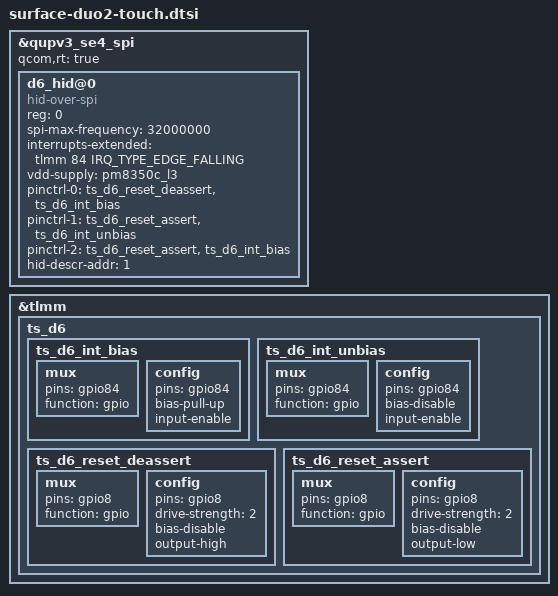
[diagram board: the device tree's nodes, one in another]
/*
 * Copyright (c) 2020 Microsoft Corporation
 *
 * This program is free software; you can redistribute it and/or modify it
 * under the terms of the GNU General Public License version 2 as published by
 * the Free Software Foundation.
 */
#include <dt-bindings/interrupt-controller/irq.h>

&qupv3_se4_spi {
	status = "okay";
	qcom,rt = "true";

	d6_hid@0 {
		compatible = "hid-over-spi";
		reg = <0>;
		spi-max-frequency = <32000000>;
		interrupts-extended = <&tlmm 84 IRQ_TYPE_EDGE_FALLING>;
		interrupt-names = "d6_irq";
		vdd-supply = <&pm8350c_l3>;
		pinctrl-names = "active", "sleep", "reset";
		pinctrl-0 = <&ts_d6_reset_deassert &ts_d6_int_bias>;
		pinctrl-1 = <&ts_d6_reset_assert &ts_d6_int_unbias>;
		pinctrl-2 = <&ts_d6_reset_assert &ts_d6_int_bias>;
		hid-descr-addr = <1>;
	};
};

&tlmm {
	ts_d6 {
		ts_d6_int_bias: ts_d6_int_bias {
			mux {
				pins = "gpio84";
				function = "gpio";
			};

			config {
				pins = "gpio84";
				bias-pull-up;
				input-enable;
			};
		};

		ts_d6_int_unbias: ts_d6_int_unbias {
			mux {
				pins = "gpio84";
				function = "gpio";
			};

			config {
				pins = "gpio84";
				bias-disable;
				input-enable;
			};
		};

		ts_d6_reset_deassert: ts_d6_reset_deassert {
			mux {
				pins = "gpio8";
				function = "gpio";
			};

			config {
				pins = "gpio8";
				drive-strength = <2>;
				bias-disable;
				output-high;
			};
		};

		ts_d6_reset_assert: ts_d6_reset_assert {
			mux {
				pins = "gpio8";
				function = "gpio";
			};

			config {
				pins = "gpio8";
				drive-strength = <2>;
				bias-disable;
				output-low;
			};
		};
	};
};
